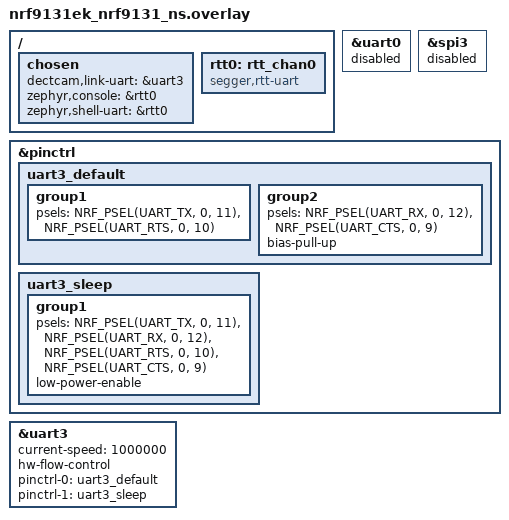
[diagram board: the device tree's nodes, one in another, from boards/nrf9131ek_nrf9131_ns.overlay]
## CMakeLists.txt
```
cmake_minimum_required(VERSION 3.20.0)

find_package(Zephyr REQUIRED HINTS $ENV{ZEPHYR_BASE})

project(dect_cam_rx)

target_sources(app PRIVATE
    src/main.c
    src/radio.c
    src/uart_out.c
    src/ctrl.c
)

target_include_directories(app PRIVATE ${CMAKE_CURRENT_SOURCE_DIR}/../common)
```

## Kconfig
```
# rsource, not source: plain `source` resolves against $srctree (ZEPHYR_BASE),
# whereas rsource is relative to this file.
rsource "../common/Kconfig.dectcam"

menu "DECT camera receiver"

config DECTCAM_RX_UART_BAUD
	int "Baud rate of the VCOM1 link to the PC"
	default 1000000
	help
	  1 Mbaud is the nRF9151 UARTE maximum and was measured to carry
	  81 kB/s losslessly through the DK's interface MCU, provided
	  hardware flow control is enabled.

config DECTCAM_RX_RING_SIZE
	int "Output ring buffer size (bytes)"
	default 16384
	help
	  Absorbs bursts from the radio while the 1 Mbaud VCOM drains.

	  When it overflows the NEWEST packet is dropped rather than
	  corrupting what is already queued, because a partial packet at the
	  PC costs a resynchronisation.

config DECTCAM_RX_STATS_PACKETS
	bool "Send link statistics to the PC"
	default y
	help
	  Emit a STATS packet about once a second carrying RSSI, SNR and PDC
	  counters, so the viewer HUD can show link quality.

endmenu

menu "Zephyr Kernel"
source "Kconfig.zephyr"
endmenu
```

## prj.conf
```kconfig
# DECT camera receiver

CONFIG_TFM_PROFILE_TYPE_MINIMAL=y

# Modem + DECT NR+ PHY
CONFIG_NRF_MODEM_LIB=y
CONFIG_NRF_MODEM_LINK_BINARY_DECT_PHY=y
CONFIG_MODEM_ANTENNA=n

CONFIG_HWINFO=y

# Link uart -> VCOM1 -> USB. Async so EasyDMA streams without a per-byte
# interrupt. Which UART instance that is depends on the board, so the
# per-instance switches live in boards/<board>.conf next to the overlay that
# chooses it.
CONFIG_SERIAL=y
CONFIG_UART_ASYNC_API=y
CONFIG_RING_BUFFER=y

CONFIG_LOG=y
CONFIG_LOG_BUFFER_SIZE=4096
# Without this Zephyr renders every %f in a log message as the literal
# "*float*", which silently destroys all the rate statistics.
CONFIG_CBPRINTF_FP_SUPPORT=y
# Deferred: logging happens on VCOM0 and must never stall the radio callback
# or the VCOM1 data path.
CONFIG_LOG_MODE_DEFERRED=y

CONFIG_MAIN_STACK_SIZE=4096
CONFIG_SYSTEM_WORKQUEUE_STACK_SIZE=2048

CONFIG_ASSERT=y
CONFIG_RESET_ON_FATAL_ERROR=n
```

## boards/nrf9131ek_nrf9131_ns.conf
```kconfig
# Per-instance UART switches for the nRF9131 EK, where the link is uart3.
#
# Instance 2 is not available here: on the nRF91 each instance number is shared
# by SPIM, SPIS, TWIM, TWIS and UARTE, and the EK spends instance 2 on i2c2 for
# the nPM1300 PMIC. Instance 3 is spent on spi3 for an external flash that the
# board already leaves disabled, so the overlay reclaims it.
#
# Stated explicitly even though nothing here enables interrupt-driven UART
# today: on the transmitter, adding the shell flipped the link uart to
# interrupt-driven and silently broke the async API. Pin it down so the same
# trap cannot be sprung by a future addition.
CONFIG_UART_3_INTERRUPT_DRIVEN=n
CONFIG_UART_3_ASYNC=y

# See the note in the overlay: the EK corrupts large packets with the
# low-power async mode on.
CONFIG_UART_3_NRF_ASYNC_LOW_POWER=n

# Console over RTT: uart0 now carries video, and the console was unusable
# during streaming anyway.
CONFIG_USE_SEGGER_RTT=y
CONFIG_RTT_CONSOLE=y
CONFIG_UART_CONSOLE=n
```

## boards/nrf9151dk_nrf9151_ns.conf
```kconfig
# Per-instance UART switches for the nRF9151 DK, where the link is uart2.
#
# These cannot live in prj.conf: the symbol name carries the instance number,
# and the nRF9131 EK has to use uart3 because instance 2 is its PMIC i2c.
#
# Stated explicitly even though nothing here enables interrupt-driven UART
# today: on the transmitter, adding the shell flipped the link uart to
# interrupt-driven and silently broke the async API. Pin it down so the same
# trap cannot be sprung by a future addition.
CONFIG_UART_2_INTERRUPT_DRIVEN=n
CONFIG_UART_2_ASYNC=y
```

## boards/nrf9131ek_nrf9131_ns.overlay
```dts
/*
 * Receiver on the nRF9131 EK (PCA10165): video over VCOM0, console over RTT.
 *
 *   P0.11 = TX  -> VCOM0 -> host
 *   P0.12 = RX  <- VCOM0 <- host
 *   P0.10 = RTS
 *   P0.09 = CTS
 *
 * No wiring: the receiver needs no header pins at all, on either connector.
 *
 * Why not VCOM1, which is where the DK puts it
 * ---------------------------------------------
 * VCOM1 works, but only for a trickle. Measured with video flowing, the
 * receiver checked its own CRC on every packet the instant the modem handed it
 * over and found not one bad -- 951 fragments queued, 0 corrupt, DECT CRC
 * errors 0, outbound ring never above empty -- and the PC still saw 553 of
 * those 951 arrive with a broken CRC. Clean in, clean out, ruined in between.
 *
 * The reason is that the EK does not connect RTS/CTS on VCOM1. Nothing can
 * tell the receiver to wait, so whenever the interface MCU is busy the bytes
 * in flight are simply gone. It is not a bandwidth problem and it does not
 * respond to the usual levers: baud 1 M, 460800 and 115200 all fail, and the
 * slower ones fail harder; fragment payloads of 687 and 128 bytes fail alike;
 * chunk sizes of 512 and 2048 make no difference; nor does turning off the
 * low-power async mode. Only the tiny packets sent while the line is otherwise
 * idle -- metadata, statistics -- survive reliably.
 *
 * uart0 is the console on VCOM0, and unlike uart1 the board's own device tree
 * gives it a full four-wire pinctrl including RTS and CTS. If those are wired
 * through, this is the port that can carry video. The console moves to RTT,
 * which costs nothing here: it was unusable during streaming anyway, because
 * both virtual COM ports share one USB device and the video starves the
 * console.
 *
 * Instance 3 rather than 2, as everywhere on this board: on the nRF91 each
 * instance number is shared by SPIM, SPIS, TWIM, TWIS and UARTE, instance 2 is
 * the nPM1300's i2c2, and instance 3 is only an already-disabled flash.
 */

/ {
	chosen {
		/* Which instance carries the video, so the source does not have
		 * to know. The two boards cannot agree on a number. */
		dectcam,link-uart = &uart3;

		zephyr,console = &rtt0;
		zephyr,shell-uart = &rtt0;
	};

	rtt0: rtt_chan0 {
		compatible = "segger,rtt-uart";
		status = "okay";
	};
};

/* uart0 owns the VCOM0 pads by default; uart3 is taking them over. */
&uart0 {
	status = "disabled";
};

/* Frees instance 3 for uart3. Only the external flash used it, and that flash
 * is already disabled in the board's device tree. */
&spi3 {
	status = "disabled";
};

&pinctrl {
	uart3_default: uart3_default {
		group1 {
			psels = <NRF_PSEL(UART_TX, 0, 11)>,
				<NRF_PSEL(UART_RTS, 0, 10)>;
		};
		group2 {
			psels = <NRF_PSEL(UART_RX, 0, 12)>,
				<NRF_PSEL(UART_CTS, 0, 9)>;
			bias-pull-up;
		};
	};

	uart3_sleep: uart3_sleep {
		group1 {
			psels = <NRF_PSEL(UART_TX, 0, 11)>,
				<NRF_PSEL(UART_RX, 0, 12)>,
				<NRF_PSEL(UART_RTS, 0, 10)>,
				<NRF_PSEL(UART_CTS, 0, 9)>;
			low-power-enable;
		};
	};
};

&uart3 {
	status = "okay";
	current-speed = <1000000>;
	hw-flow-control;
	pinctrl-0 = <&uart3_default>;
	pinctrl-1 = <&uart3_sleep>;
	pinctrl-names = "default", "sleep";
};
```

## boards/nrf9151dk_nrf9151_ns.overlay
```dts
/*
 * Receiver: uart2 routed to the nRF9151 DK's VCOM1 pins, so the video stream
 * leaves the board over the same USB-C cable that powers it.
 *
 *   P0.29 = TX  -> VCOM1 -> host
 *   P0.28 = RX  <- VCOM1 <- host
 *   P0.16 = RTS
 *   P0.17 = CTS
 *
 * Verified on hardware: these pads do reach VCOM1, which appears as the
 * SECOND of the two serial ports the DK enumerates.
 *
 * uart1 would be the natural choice for these pins, but
 * nrf9151dk_nrf9151_ns.dts disables it because TF-M claims it for secure
 * logging. uart2 is free and the nRF91 pin matrix allows any pad.
 *
 * hw-flow-control is REQUIRED, not optional. Measured over 20 s of continuous
 * 1 Mbaud traffic:
 *     without RTS/CTS : 80.4 kB/s, 13.1 % of blocks lost
 *     with    RTS/CTS : 81.0 kB/s, 0.00 % lost
 * Without it the USB path silently discards bytes and video is unusable.
 */

/ {
	chosen {
		/* Which instance carries the video, so the source does not have to
		 * know. The nRF9131 EK cannot use uart2 -- instance 2 is its PMIC
		 * i2c -- so the number is a board property, not an application one. */
		dectcam,link-uart = &uart2;
	};
};

&pinctrl {
	uart2_default: uart2_default {
		group1 {
			psels = <NRF_PSEL(UART_TX, 0, 29)>,
				<NRF_PSEL(UART_RTS, 0, 16)>;
		};
		group2 {
			psels = <NRF_PSEL(UART_RX, 0, 28)>,
				<NRF_PSEL(UART_CTS, 0, 17)>;
			bias-pull-up;
		};
	};

	uart2_sleep: uart2_sleep {
		group1 {
			psels = <NRF_PSEL(UART_TX, 0, 29)>,
				<NRF_PSEL(UART_RX, 0, 28)>,
				<NRF_PSEL(UART_RTS, 0, 16)>,
				<NRF_PSEL(UART_CTS, 0, 17)>;
			low-power-enable;
		};
	};
};

&uart2 {
	status = "okay";
	current-speed = <1000000>;
	hw-flow-control;
	pinctrl-0 = <&uart2_default>;
	pinctrl-1 = <&uart2_sleep>;
	pinctrl-names = "default", "sleep";
};
```

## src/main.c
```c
/*
 * main.c - DECT NR+ camera link, receiver.
 *
 * SPDX-License-Identifier: Apache-2.0
 *
 * Receives dectcam packets over DECT NR+ and forwards each one verbatim to the
 * PC over VCOM1. Like the transmitter, this side does not interpret the video
 * at all: it is a pump with a statistics side-channel.
 *
 * The PC sees the SECOND serial port the DK enumerates (VCOM1), and must open
 * it with RTS/CTS enabled -- see docs/wiring.md.
 */

#include <zephyr/kernel.h>
#include <zephyr/logging/log.h>
#include <zephyr/drivers/gpio.h>

#include "radio.h"
#include "uart_out.h"
#include "ctrl.h"
#include "dectcam_cfg.h"

LOG_MODULE_REGISTER(dectcam_rx, CONFIG_DECTCAM_LOG_LEVEL);

/* LED0 = radio up, LED1 = RX activity. */
static const struct gpio_dt_spec led_up = GPIO_DT_SPEC_GET(DT_ALIAS(led0), gpios);
static const struct gpio_dt_spec led_rx = GPIO_DT_SPEC_GET(DT_ALIAS(led1), gpios);

static uint32_t s_forwarded;
static uint32_t s_malformed;

/* Packets whose CRC was already wrong when the modem handed them to us. */
static uint32_t s_rx_crc_bad;
static uint32_t s_padding_saved;

/*
 * Modem callback context: do the minimum.
 *
 * The PDC is always a whole transport block (700 B at MCS 4 / 8 subslots),
 * so a packet shorter than that arrives padded with whatever the modem put
 * after it. Forwarding the padding would waste the VCOM1 link -- which at
 * 81 kB/s is the tightest bottleneck in the system -- and would force the PC
 * decoder to resynchronise after every short fragment.
 *
 * So read the length out of the header and forward exactly the real packet.
 * The header is validated first: a corrupted length must never be trusted.
 */
static void on_pdc(const uint8_t *data, size_t len)
{
	if (len < DECTCAM_HDR_LEN || data[0] != DECTCAM_MAGIC0 || data[1] != DECTCAM_MAGIC1 ||
	    (data[DECTCAM_OFF_VERTYPE] >> 4) != DECTCAM_VERSION) {
		s_malformed++;
		return;
	}

	const uint16_t plen = dectcam_get_u16(&data[DECTCAM_OFF_PAYLOAD_LEN]);
	const size_t total = (size_t)plen + DECTCAM_OVERHEAD;

	if (plen > DECTCAM_MAX_PAYLOAD || total > len) {
		s_malformed++;
		return;
	}

	/*
	 * Acknowledgements ride the video stream, because that direction
	 * already works. Let the control logic see them on the way past; they
	 * are forwarded to the host as well, so the viewer can report what
	 * happened.
	 */
	if (data[DECTCAM_OFF_VERTYPE] % 16 == DECTCAM_TYPE_CTRL) {
		ctrl_on_air_packet(data, total);
	}

	/*
	 * Check our own CRC here, the instant the modem hands the packet over,
	 * and before it goes anywhere near the ring or the UART.
	 *
	 * This settles an argument the other measurements could not. The DECT
	 * layer reports pdc_crc_err = 0, so the radio delivered every packet
	 * intact, and yet the PC sees about 60 % of them fail this same CRC.
	 * The damage is therefore somewhere between the modem checking the
	 * packet and the PC receiving it -- and that span contains both the
	 * copy out of the modem's buffer and the whole UART path. Counting
	 * failures here splits it in two: a non-zero count means the bytes
	 * were already wrong when we got them, a zero count means we sent
	 * good data and something downstream ruined it.
	 */
	{
		const uint16_t want = dectcam_crc16(&data[DECTCAM_OFF_VERTYPE],
						    (size_t)(DECTCAM_HDR_LEN - 2u) + plen);
		const uint16_t got = dectcam_get_u16(&data[DECTCAM_OFF_PAYLOAD + plen]);

		if (want != got) {
			s_rx_crc_bad++;
		}
	}

	if (uart_out_send(data, total) == 0) {
		s_forwarded++;
		s_padding_saved += (uint32_t)(len - total);
		if ((s_forwarded & 0x0f) == 0) {
			gpio_pin_toggle_dt(&led_rx);
		}
	}
}

static void leds_init(void)
{
	if (gpio_is_ready_dt(&led_up)) {
		gpio_pin_configure_dt(&led_up, GPIO_OUTPUT_INACTIVE);
	}
	if (gpio_is_ready_dt(&led_rx)) {
		gpio_pin_configure_dt(&led_rx, GPIO_OUTPUT_INACTIVE);
	}
}

#if CONFIG_DECTCAM_RX_STATS_PACKETS
static void send_stats_packet(void)
{
	struct radio_stats rs;
	struct uart_out_stats us;

	radio_get_stats(&rs);
	uart_out_get_stats(&us);

	struct dectcam_stats s = {
		.rssi_2 = rs.last_rssi_2,
		.snr = rs.last_snr,
		.pdc_ok = rs.pdc_ok,
		.pdc_crc_err = rs.pdc_crc_err,
		.frags_out = us.queued,
		.ring_peak = (uint16_t)MIN(uart_out_take_peak(), UINT16_MAX),
		.rx_crc_bad = (uint16_t)MIN(s_rx_crc_bad, UINT16_MAX),
	};
	uint8_t body[DECTCAM_STATS_LEN];
	uint8_t pkt[DECTCAM_STATS_LEN + DECTCAM_OVERHEAD];

	dectcam_stats_pack(body, &s);

	const size_t n = dectcam_encode(pkt, sizeof(pkt), DECTCAM_TYPE_STATS, 0, 0, 0, body,
					sizeof(body));

	if (n) {
		uart_out_send(pkt, n);
	}
}
#endif

int main(void)
{
	LOG_INF("DECT camera receiver starting");

	leds_init();

	ctrl_init();

	if (uart_out_init() != 0) {
		LOG_ERR("uart init failed; halting");
		return -EIO;
	}
	uart_out_set_rx_cb(ctrl_feed_host);

	if (radio_init(on_pdc) != 0) {
		LOG_ERR("radio init failed; halting");
		return -EIO;
	}

	if (radio_start_rx() != 0) {
		LOG_ERR("could not start RX; halting");
		return -EIO;
	}
	gpio_pin_set_dt(&led_up, 1);

	LOG_INF("receiving; forwarding to VCOM1");

	int64_t last_stats = k_uptime_get();
	int64_t last_statpkt = k_uptime_get();
	uint32_t last_pdc_ok;
	uint64_t last_bytes;

	{
		struct radio_stats rs;

		radio_get_stats(&rs);
		last_pdc_ok = rs.pdc_ok;
		last_bytes = rs.rx_bytes;
	}

	for (;;) {
		/*
		 * 20 ms rather than 100: control telegrams are repeated from
		 * here, and the transmitter's listen window is only 20 ms wide
		 * every 250 ms, so a slower loop would miss most of them.
		 */
		k_msleep(20);

		ctrl_poll();

		const int64_t now = k_uptime_get();

#if CONFIG_DECTCAM_RX_STATS_PACKETS
		if (now - last_statpkt >= 1000) {
			send_stats_packet();
			last_statpkt = now;
		}
#endif

#if CONFIG_DECTCAM_STATS_INTERVAL_MS > 0
		if (now - last_stats >= CONFIG_DECTCAM_STATS_INTERVAL_MS) {
			const double secs = (now - last_stats) / 1000.0;
			struct radio_stats rs;
			struct uart_out_stats us;

			radio_get_stats(&rs);
			uart_out_get_stats(&us);

			LOG_INF("rx %.1f pkt/s, %.1f kB/s | rssi %d.%d dBm snr %d.%02d dB | "
				"pdc ok %u crc %u | pcc ok %u crc %u | "
				"uart q %u drop %u | malformed %u | pad saved %u kB | "
				"rx restarts %u",
				(rs.pdc_ok - last_pdc_ok) / secs,
				(rs.rx_bytes - last_bytes) / secs / 1000.0, rs.last_rssi_2 / 2,
				(rs.last_rssi_2 & 1) * 5, rs.last_snr / 4,
				(rs.last_snr % 4) * 25, rs.pdc_ok, rs.pdc_crc_err, rs.pcc_ok,
				rs.pcc_crc_err, us.queued, us.dropped, s_malformed,
				s_padding_saved / 1024, rs.rx_restarts);

			last_pdc_ok = rs.pdc_ok;
			last_bytes = rs.rx_bytes;
			last_stats = now;
		}
#endif
	}

	return 0;
}
```

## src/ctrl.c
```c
/*
 * ctrl.c - control from the PC, receiver side.
 *
 * SPDX-License-Identifier: Apache-2.0
 *
 * The operator's commands arrive here, on the same USB serial port that
 * carries video the other way, and are relayed over the air to the
 * transmitter. This side is the one that knows whether a command worked,
 * because it can see the acknowledgement come back in the video stream.
 *
 * A telegram is repeated until it is acknowledged or the attempt times out.
 * That is not belt and braces: the transmitter only listens for 20 ms out of
 * every 250, so a single copy would usually be missed.
 */

#include <zephyr/kernel.h>
#include <zephyr/logging/log.h>

#include "ctrl.h"
#include "radio.h"
#include "dectcam_cfg.h"

LOG_MODULE_DECLARE(dectcam_rx, CONFIG_DECTCAM_LOG_LEVEL);

/*
 * A burst of copies, close enough together that any listen window at the far
 * end catches several.
 *
 * The transmitter listens for 30 ms out of every 200. Copies 25 ms apart mean
 * at least one lands in every window, and 40 of them span a full second --
 * five windows. Reception is stopped for that second, so this is deliberately
 * a one-off cost rather than a background trickle.
 */
#define BURST_COUNT  40
#define BURST_GAP_MS 25

/* How long to wait for the acknowledgement, and how many bursts to try. */
#define ACK_WAIT_MS  1500
#define MAX_BURSTS   3

/*
 * Carrier rollback deadline.
 *
 * Deliberately shorter than the transmitter's 6 s trial. If the move fails,
 * this end returns first and is already listening on the old carrier by the
 * time the far end follows -- the two converge instead of crossing over, which
 * is what would happen if both used the same deadline and drifted apart.
 */
#define CARRIER_TRIAL_MS 4000

static struct ctrl_stats s_stats;

/* The telegram currently being sent, if any. */
static bool s_busy;
static uint8_t s_opcode;
static uint32_t s_arg;
static uint8_t s_seq;
static int s_bursts_done;
static int64_t s_wait_until;

/* Carrier trial state. */
static bool s_carrier_trial;
static uint16_t s_carrier_previous;
static uint16_t s_carrier_target;
static int64_t s_carrier_deadline;
static uint32_t s_pdc_at_switch;

/*
 * Sequence numbers for telegrams this end originates rather than relays --
 * currently only the carrier confirmation. Kept well away from the host's
 * numbering by counting down from the top, so the two cannot collide and
 * suppress one another as duplicates.
 */
static uint8_t s_own_seq = 255;

/* Reassembles packets arriving from the host, which need not be aligned. */
static uint8_t s_host_buf[128];
static size_t s_host_len;

/*
 * Start sending a telegram.
 *
 * `seq` comes from the host and is carried through unchanged, so the
 * acknowledgement that eventually comes back can be matched to the command
 * that caused it -- by the transmitter for de-duplication, and by the operator
 * at the far end of the USB cable.
 *
 * De-duplication at the far end compares against the previous sequence only,
 * so a host that restarts and reuses a number does not lose a command; it
 * would have to reuse the number twice in a row.
 */
static void send_burst(uint8_t opcode, uint8_t seq, uint32_t arg)
{
	uint8_t pkt[DECTCAM_CTRL_LEN + DECTCAM_OVERHEAD];
	const size_t n = dectcam_encode_ctrl(pkt, sizeof(pkt), opcode, seq, arg);

	if (n == 0) {
		return;
	}
	if (radio_send_ctrl_burst(pkt, n, BURST_COUNT, BURST_GAP_MS) == 0) {
		s_stats.sent++;
	}
}

static void start(uint8_t opcode, uint8_t seq, uint32_t arg)
{
	s_busy = true;
	s_opcode = opcode;
	s_arg = arg;
	s_seq = seq;
	s_bursts_done = 0;
	s_wait_until = 0; /* burst immediately */
}

/*
 * Begin a carrier change.
 *
 * Unlike every other command, this one does NOT wait for an acknowledgement
 * before acting -- it cannot. The far end applies the new carrier the moment
 * it hears the telegram and starts transmitting there, including its
 * acknowledgement. This end is still on the old carrier and so never hears it.
 * Waiting for one leaves the two ends on different channels with no way to
 * reach each other, which is exactly what happened the first time this was
 * tried: the link went dead and only a reset brought it back.
 *
 * So both ends move on their own clocks instead. This one announces the change
 * for the length of one burst, then retunes regardless. Each side then watches
 * for traffic and returns to the old carrier on its own if none appears -- this
 * end first, so the two converge on the old channel rather than crossing over.
 */
static void begin_carrier_change(uint8_t seq, uint16_t carrier)
{
	s_carrier_previous = radio_carrier();
	s_carrier_target = carrier;

	LOG_WRN("announcing carrier %u -> %u", s_carrier_previous, carrier);

	uint8_t pkt[DECTCAM_CTRL_LEN + DECTCAM_OVERHEAD];
	const size_t n = dectcam_encode_ctrl(pkt, sizeof(pkt), DECTCAM_CTRL_SET_CARRIER,
					     seq, carrier);

	if (n == 0) {
		return;
	}

	/* One burst on the old carrier: five of the far end's listen windows. */
	radio_send_ctrl_burst(pkt, n, BURST_COUNT, BURST_GAP_MS);
	s_stats.sent++;

	/* Now follow it, and start the clock. */
	struct radio_stats rs;

	radio_get_stats(&rs);
	s_pdc_at_switch = rs.pdc_ok;
	s_carrier_trial = true;
	s_carrier_deadline = k_uptime_get() + CARRIER_TRIAL_MS;
	s_stats.carrier_moves++;

	radio_set_carrier(carrier);
	LOG_WRN("now on %u; returning to %u in %d ms unless video appears", carrier,
		s_carrier_previous, CARRIER_TRIAL_MS);
}

void ctrl_init(void)
{
	s_host_len = 0;
}

/*
 * Command from the host, waiting to be acted on.
 *
 * ctrl_feed_host() runs in the UART interrupt. Acting on a command there is
 * not merely impolite, it is fatal: a carrier change transmits a burst, and
 * the burst sleeps between copies. k_msleep() from an interrupt takes the
 * board down, which is precisely what happened -- the receiver went silent and
 * only a reset brought it back, while the transmitter carried on happily
 * announcing itself on a carrier nobody was listening to.
 *
 * So the interrupt parks the command and the main loop runs it.
 */
static volatile bool s_inbox_full;
static struct dectcam_ctrl s_inbox;

static void handle_from_host(const struct dectcam_ctrl *c)
{
	s_stats.from_host++;

	if (s_busy || s_inbox_full) {
		LOG_WRN("a command is already in flight; ignoring opcode %u", c->opcode);
		return;
	}

	s_inbox = *c;
	s_inbox_full = true;
}

static void process_inbox(void)
{
	if (!s_inbox_full) {
		return;
	}

	const struct dectcam_ctrl c = s_inbox;

	s_inbox_full = false;

	if (c.opcode == DECTCAM_CTRL_SET_CARRIER) {
		begin_carrier_change(c.seq, (uint16_t)c.arg32);
	} else {
		start(c.opcode, c.seq, c.arg32);
	}
}

void ctrl_feed_host(const uint8_t *data, size_t len)
{
	for (size_t i = 0; i < len; i++) {
		if (s_host_len < sizeof(s_host_buf)) {
			s_host_buf[s_host_len++] = data[i];
		} else {
			/* Nothing valid in a full buffer: start over. */
			s_host_len = 0;
		}

		/* Try to pull a packet out of what we have so far. */
		while (s_host_len >= DECTCAM_HDR_LEN) {
			struct dectcam_pkt pkt;
			size_t consumed = 0;
			const int rc = dectcam_decode(s_host_buf, s_host_len, &pkt, &consumed);

			if (rc == DECTCAM_ERR_SHORT) {
				break;
			}
			if (rc != DECTCAM_OK) {
				/* Resynchronise one byte at a time. */
				memmove(s_host_buf, s_host_buf + 1, --s_host_len);
				continue;
			}

			if (pkt.type == DECTCAM_TYPE_CTRL &&
			    pkt.payload_len >= DECTCAM_CTRL_LEN) {
				struct dectcam_ctrl c;

				dectcam_ctrl_unpack(pkt.payload, &c);
				handle_from_host(&c);
			}

			memmove(s_host_buf, s_host_buf + consumed, s_host_len - consumed);
			s_host_len -= consumed;
		}
	}
}

void ctrl_on_air_packet(const uint8_t *data, size_t len)
{
	struct dectcam_pkt pkt;
	size_t consumed;

	if (dectcam_decode(data, len, &pkt, &consumed) != DECTCAM_OK) {
		return;
	}
	if (pkt.type != DECTCAM_TYPE_CTRL || pkt.payload_len < DECTCAM_CTRL_LEN) {
		return;
	}

	struct dectcam_ctrl c;

	dectcam_ctrl_unpack(pkt.payload, &c);

	if (c.opcode != DECTCAM_CTRL_ACK || !s_busy || c.seq != s_seq) {
		return;
	}

	s_busy = false;
	s_stats.acked++;

	if (c.arg32 != DECTCAM_ACK_OK) {
		LOG_WRN("far end rejected opcode %u (status %u)", s_opcode,
			(unsigned)c.arg32);
	}
}

void ctrl_poll(void)
{
	const int64_t now = k_uptime_get();

	process_inbox();

	if (s_carrier_trial) {
		struct radio_stats rs;

		radio_get_stats(&rs);

		if (rs.pdc_ok > s_pdc_at_switch) {
			/* Video is arriving: the move worked. Tell the far end
			 * so it stops its own rollback timer. */
			s_carrier_trial = false;
			LOG_INF("video on carrier %u; confirming", s_carrier_target);
			send_burst(DECTCAM_CTRL_CARRIER_OK, s_own_seq--, s_carrier_target);
			if (s_own_seq < 128) {
				s_own_seq = 255;
			}
		} else if (now >= s_carrier_deadline) {
			s_carrier_trial = false;
			s_stats.carrier_rollbacks++;
			LOG_ERR("no video on %u; returning to %u", s_carrier_target,
				s_carrier_previous);
			radio_set_carrier(s_carrier_previous);
		}
	}

	if (!s_busy) {
		return;
	}

	/* Still waiting for the acknowledgement from the last burst. */
	if (now < s_wait_until) {
		return;
	}

	if (s_bursts_done >= MAX_BURSTS) {
		s_busy = false;
		s_stats.timed_out++;
		LOG_WRN("no acknowledgement for opcode %u after %d bursts", s_opcode,
			MAX_BURSTS);
		return;
	}

	s_bursts_done++;
	send_burst(s_opcode, s_seq, s_arg);
	s_wait_until = k_uptime_get() + ACK_WAIT_MS;
}

void ctrl_get_stats(struct ctrl_stats *out)
{
	if (out) {
		*out = s_stats;
	}
}
```

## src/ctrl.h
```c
/*
 * ctrl.h - control from the PC, receiver side.
 *
 * SPDX-License-Identifier: Apache-2.0
 */

#ifndef DECTCAM_RX_CTRL_H
#define DECTCAM_RX_CTRL_H

#include <stdint.h>
#include <stddef.h>

void ctrl_init(void);

/*
 * Feed bytes arriving from the PC on the data port.
 *
 * That port is normally write-only from this end -- it carries video to the
 * host -- but it is a full-duplex UART, so the host can send control packets
 * back along it without any extra wiring.
 */
void ctrl_feed_host(const uint8_t *data, size_t len);

/* Hand a packet that arrived over the air to the control logic. */
void ctrl_on_air_packet(const uint8_t *data, size_t len);

/* Give the control logic a slice of the main loop: repeats and timeouts. */
void ctrl_poll(void);

struct ctrl_stats {
	uint32_t from_host;
	uint32_t sent;          /* telegrams put on the air, including repeats */
	uint32_t acked;
	uint32_t timed_out;
	uint32_t carrier_moves;
	uint32_t carrier_rollbacks;
};

void ctrl_get_stats(struct ctrl_stats *out);

#endif /* DECTCAM_RX_CTRL_H */
```

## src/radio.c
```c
/*
 * radio.c - DECT NR+ PHY receive wrapper.
 *
 * SPDX-License-Identifier: Apache-2.0
 *
 * Keeps the PHY in continuous receive and hands every good PDC to a callback.
 */

#include <zephyr/kernel.h>
#include <zephyr/logging/log.h>
#include <zephyr/drivers/hwinfo.h>

#include <nrf_modem_dect_phy.h>
#include <modem/nrf_modem_lib.h>

#include "radio.h"
#include "dectcam_cfg.h"

LOG_MODULE_REGISTER(radio, CONFIG_DECTCAM_LOG_LEVEL);

BUILD_ASSERT(CONFIG_DECTCAM_CARRIER != 0,
	     "CONFIG_DECTCAM_CARRIER must be set according to local regulations");

static uint16_t s_device_id;
static struct radio_stats s_stats;
static radio_pdc_cb_t s_pdc_cb;

/* Live carrier. Seeded from Kconfig, retuned at run time when the operator
 * moves the link -- see ctrl.c for the sequence that keeps both ends together.
 */
static uint16_t s_carrier = CONFIG_DECTCAM_CARRIER;

static K_SEM_DEFINE(op_sem, 0, 1);
static volatile int s_op_err;
static bool s_fatal;

/*
 * Whether reception should be running.
 *
 * Continuous RX ends on its own after `duration` and is restarted from a work
 * item. That auto-restart has to be suppressed while the radio is borrowed for
 * a transmit, or the restart races the transmit and one of the two is
 * rejected.
 */
static volatile bool s_rx_wanted;

#define RX_HANDLE 1u
#define TX_HANDLE 0u

/*
 * Continuous RX still ends after `duration`, so it is restarted from a work
 * item when it completes. Using the modem's maximum keeps the restart rate --
 * and therefore the gap in coverage -- as low as possible.
 */
#define RX_DURATION_S 60

static void rx_restart_work_fn(struct k_work *work);
static K_WORK_DEFINE(rx_restart_work, rx_restart_work_fn);

static void handle_common(int err)
{
	s_op_err = err;
	k_sem_give(&op_sem);
}

static void dect_phy_event_handler(const struct nrf_modem_dect_phy_event *evt)
{
	switch (evt->id) {
	case NRF_MODEM_DECT_PHY_EVT_INIT:
		if (evt->init.err) {
			LOG_ERR("PHY init failed: %d", evt->init.err);
			s_fatal = true;
		}
		handle_common(evt->init.err);
		break;
	case NRF_MODEM_DECT_PHY_EVT_CONFIGURE:
		if (evt->configure.err) {
			LOG_ERR("PHY configure failed: %d", evt->configure.err);
			s_fatal = true;
		}
		handle_common(evt->configure.err);
		break;
	case NRF_MODEM_DECT_PHY_EVT_ACTIVATE:
		if (evt->activate.err) {
			LOG_ERR("PHY activate failed: %d", evt->activate.err);
			s_fatal = true;
		}
		handle_common(evt->activate.err);
		break;

	case NRF_MODEM_DECT_PHY_EVT_PCC:
		s_stats.pcc_ok++;
		s_stats.last_rssi_2 = evt->pcc.rssi_2;
		s_stats.last_snr = evt->pcc.snr;
		break;
	case NRF_MODEM_DECT_PHY_EVT_PCC_ERROR:
		s_stats.pcc_crc_err++;
		break;

	case NRF_MODEM_DECT_PHY_EVT_PDC:
		s_stats.pdc_ok++;
		s_stats.rx_bytes += evt->pdc.len;
		s_stats.last_rssi_2 = evt->pdc.rssi_2;
		s_stats.last_snr = evt->pdc.snr;
		if (s_pdc_cb) {
			s_pdc_cb((const uint8_t *)evt->pdc.data, evt->pdc.len);
		}
		break;
	case NRF_MODEM_DECT_PHY_EVT_PDC_ERROR:
		s_stats.pdc_crc_err++;
		break;

	case NRF_MODEM_DECT_PHY_EVT_COMPLETED:
		/*
		 * Either the RX window elapsed or a transmit finished. Release
		 * anyone waiting, then restart reception -- but only if it is
		 * still wanted, so a deliberate stop is not undone.
		 *
		 * Restarting happens from a work item because calling back into
		 * the modem from its own callback is not allowed.
		 */
		handle_common(evt->op_complete.err);
		if (s_rx_wanted) {
			k_work_submit(&rx_restart_work);
		}
		break;
	case NRF_MODEM_DECT_PHY_EVT_CANCELED:
		handle_common(evt->cancel.err);
		break;
	case NRF_MODEM_DECT_PHY_EVT_REJECT:
		LOG_WRN("operation rejected");
		break;
	default:
		break;
	}
}

static int step(const char *what, int err)
{
	if (err) {
		LOG_ERR("%s returned %d", what, err);
		return err;
	}
	if (k_sem_take(&op_sem, K_SECONDS(5)) != 0) {
		LOG_ERR("%s timed out waiting for its event", what);
		return -ETIMEDOUT;
	}
	if (s_fatal) {
		return -EIO;
	}
	return s_op_err;
}

int radio_start_rx(void)
{
	struct nrf_modem_dect_phy_rx_params rx = {
		.start_time = 0,
		.handle = RX_HANDLE,
		.network_id = CONFIG_DECTCAM_NETWORK_ID,
		.mode = NRF_MODEM_DECT_PHY_RX_MODE_CONTINUOUS,
		.rssi_interval = NRF_MODEM_DECT_PHY_RSSI_INTERVAL_OFF,
		.link_id = NRF_MODEM_DECT_PHY_LINK_UNSPECIFIED,
		.rssi_level = -60,
		.carrier = s_carrier,
		.duration = (uint32_t)RX_DURATION_S * MSEC_PER_SEC *
			    NRF_MODEM_DECT_MODEM_TIME_TICK_RATE_KHZ,
		.filter.short_network_id = CONFIG_DECTCAM_NETWORK_ID & 0xff,
		.filter.is_short_network_id_used = 1,
		/* Broadcast: accept from any transmitter on this network. */
		.filter.receiver_identity = 0,
	};

	s_rx_wanted = true;
	k_sem_reset(&op_sem);

	int err = nrf_modem_dect_phy_rx(&rx);

	if (err) {
		LOG_ERR("nrf_modem_dect_phy_rx failed: %d", err);
	}
	return err;
}

int radio_stop_rx(void)
{
	if (!s_rx_wanted) {
		return 0;
	}
	s_rx_wanted = false;

	int err = nrf_modem_dect_phy_cancel(RX_HANDLE);

	if (err) {
		LOG_WRN("cancel returned %d", err);
		return err;
	}

	/*
	 * Wait for the operation to actually stop. Transmitting while the
	 * receiver still owns the radio gets the transmit rejected.
	 */
	if (k_sem_take(&op_sem, K_MSEC(500)) != 0) {
		LOG_WRN("receive did not stop in time");
		return -ETIMEDOUT;
	}
	return 0;
}

/* One transmission. The caller owns stopping and restarting reception. */
static int tx_once(const uint8_t *data, size_t len)
{
	struct dectcam_phy_hdr_type1 hdr = {
		.header_format = 0,
		.packet_length_type = 0,
		.packet_length = DECTCAM_PKT_LEN_FIELD,
		.short_network_id = (CONFIG_DECTCAM_NETWORK_ID & 0xff),
		.transmitter_id_hi = (s_device_id >> 8),
		.transmitter_id_lo = (s_device_id & 0xff),
		.transmit_power = CONFIG_DECTCAM_TX_POWER,
		.reserved = 0,
		.df_mcs = CONFIG_DECTCAM_MCS,
	};

	struct nrf_modem_dect_phy_tx_params tx = {
		.start_time = 0,
		.handle = TX_HANDLE,
		.network_id = CONFIG_DECTCAM_NETWORK_ID,
		.phy_type = 0,
		.carrier = s_carrier,
		.phy_header = (union nrf_modem_dect_phy_hdr *)&hdr,
		.data = (void *)data,
		.data_size = len,
		.lbt_rssi_threshold_max = 0,
		.lbt_period = 0,
	};

	k_sem_reset(&op_sem);

	int err = nrf_modem_dect_phy_tx(&tx);

	if (err == 0) {
		if (k_sem_take(&op_sem, K_MSEC(500)) != 0) {
			err = -ETIMEDOUT;
		} else {
			err = s_op_err;
		}
	}

	if (err) {
		s_stats.ctrl_tx_err++;
	} else {
		s_stats.ctrl_tx++;
	}
	return err;
}

int radio_send_ctrl_burst(const uint8_t *data, size_t len, int count, uint32_t gap_ms)
{
	if (len == 0 || len > (size_t)DECTCAM_TBS_BYTES || count <= 0) {
		return -EINVAL;
	}

	const bool was_receiving = s_rx_wanted;

	if (was_receiving && radio_stop_rx() != 0) {
		LOG_WRN("could not stop reception; not transmitting");
		return -EBUSY;
	}

	int sent = 0;

	for (int i = 0; i < count; i++) {
		if (tx_once(data, len) == 0) {
			sent++;
		}
		if (i + 1 < count && gap_ms) {
			k_msleep(gap_ms);
		}
	}

	if (was_receiving) {
		radio_start_rx();
	}

	if (sent == 0) {
		LOG_WRN("control burst: nothing got out");
		return -EIO;
	}
	return 0;
}

int radio_set_carrier(uint16_t carrier)
{
	if (carrier == 0) {
		return -EINVAL;
	}
	if (carrier == s_carrier) {
		return 0;
	}

	const bool was_receiving = s_rx_wanted;

	if (was_receiving) {
		radio_stop_rx();
	}
	s_carrier = carrier;
	LOG_INF("carrier -> %u", carrier);

	if (was_receiving) {
		return radio_start_rx();
	}
	return 0;
}

uint16_t radio_carrier(void)
{
	return s_carrier;
}

static void rx_restart_work_fn(struct k_work *work)
{
	ARG_UNUSED(work);
	s_stats.rx_restarts++;
	radio_start_rx();
}

int radio_init(radio_pdc_cb_t cb)
{
	int err;

	s_pdc_cb = cb;

	err = nrf_modem_lib_init();
	if (err) {
		LOG_ERR("nrf_modem_lib_init failed: %d", err);
		return err;
	}

	err = nrf_modem_dect_phy_event_handler_set(dect_phy_event_handler);
	if (err) {
		LOG_ERR("event_handler_set failed: %d", err);
		return err;
	}

	err = step("dect_phy_init", nrf_modem_dect_phy_init());
	if (err) {
		return err;
	}

	struct nrf_modem_dect_phy_config_params cfg = {
		.band_group_index = CONFIG_DECTCAM_BAND_GROUP_INDEX,
		.harq_rx_process_count = 4,
		.harq_rx_expiry_time_us = 5000000,
	};

	err = step("dect_phy_configure", nrf_modem_dect_phy_configure(&cfg));
	if (err) {
		return err;
	}

	err = step("dect_phy_activate",
		   nrf_modem_dect_phy_activate(NRF_MODEM_DECT_PHY_RADIO_MODE_LOW_LATENCY));
	if (err) {
		return err;
	}

	hwinfo_get_device_id((void *)&s_device_id, sizeof(s_device_id));

	LOG_INF("DECT PHY up: device id %u, carrier %d, MCS %d, %d subslots (%d B TBS)",
		s_device_id, CONFIG_DECTCAM_CARRIER, CONFIG_DECTCAM_MCS,
		CONFIG_DECTCAM_PACKET_LEN_SUBSLOTS, DECTCAM_TBS_BYTES);

	return 0;
}

uint16_t radio_device_id(void)
{
	return s_device_id;
}

void radio_get_stats(struct radio_stats *out)
{
	if (out) {
		*out = s_stats;
	}
}
```

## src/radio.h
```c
/*
 * radio.h - DECT NR+ PHY receive wrapper.
 *
 * SPDX-License-Identifier: Apache-2.0
 */

#ifndef DECTCAM_RADIO_H
#define DECTCAM_RADIO_H

#include <stdint.h>
#include <stddef.h>

/*
 * Called from the modem event handler for every PDC that passes CRC.
 * Keep it short: it runs in the modem callback context.
 */
typedef void (*radio_pdc_cb_t)(const uint8_t *data, size_t len);

int radio_init(radio_pdc_cb_t cb);

/* Start (or restart) continuous reception. */
int radio_start_rx(void);

/* Stop the current receive operation and wait for it to wind down. */
int radio_stop_rx(void);

/*
 * Send the same control telegram `count` times, `gap_ms` apart.
 *
 * The far end listens only in short windows between video bursts, so a single
 * copy would usually be missed. Reception is stopped once for the whole burst
 * rather than once per copy: tearing it down and building it back up again for
 * every repeat cost more time than the transmissions themselves and left the
 * video badly disrupted.
 *
 * Video is not received for the duration of the burst. That is the price of
 * having one radio, and it is only paid when the operator changes something.
 */
int radio_send_ctrl_burst(const uint8_t *data, size_t len, int count, uint32_t gap_ms);

/* Retune the receiver. The far end must be moved separately and first. */
int radio_set_carrier(uint16_t carrier);

uint16_t radio_carrier(void);

uint16_t radio_device_id(void);

struct radio_stats {
	uint32_t pdc_ok;
	uint32_t pdc_crc_err;
	uint32_t pcc_ok;
	uint32_t pcc_crc_err;
	uint32_t rx_restarts;
	uint64_t rx_bytes;
	uint32_t ctrl_tx;     /* control telegrams put on the air */
	uint32_t ctrl_tx_err;
	int16_t last_rssi_2;  /* dBm * 2 */
	int16_t last_snr;     /* dB * 4  */
};

void radio_get_stats(struct radio_stats *out);

#endif /* DECTCAM_RADIO_H */
```

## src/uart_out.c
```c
/*
 * uart_out.c - buffered UART transmission to the PC over VCOM1.
 *
 * SPDX-License-Identifier: Apache-2.0
 *
 * The modem callback must return quickly, so it only appends to a ring buffer.
 * A dedicated thread drains that into the UART using the async API, so
 * EasyDMA does the work.
 *
 * Packets are queued atomically: if a whole packet does not fit, it is dropped
 * entirely rather than truncated. A torn packet would cost the PC decoder a
 * resynchronisation and would very likely corrupt the frame either way, so
 * dropping is strictly better.
 */

#include <zephyr/kernel.h>
#include <zephyr/device.h>
#include <zephyr/drivers/uart.h>
#include <zephyr/logging/log.h>
#include <zephyr/sys/ring_buffer.h>

#include "uart_out.h"
#include "dectcam_proto.h"

LOG_MODULE_DECLARE(dectcam_rx, CONFIG_DECTCAM_LOG_LEVEL);

/* Named by the board overlay, not here: the DK uses uart2 and the EK uart3,
 * because on the EK instance 2 belongs to the PMIC's i2c. */
static const struct device *const uart_dev = DEVICE_DT_GET(DT_CHOSEN(dectcam_link_uart));

RING_BUF_DECLARE(tx_ring, CONFIG_DECTCAM_RX_RING_SIZE);

/*
 * Guards the producer side of tx_ring. See uart_out_send() for why: the ring
 * buffer tolerates one producer, and this application has two.
 *
 * The consumer (pump_thread) needs no lock, since single-producer /
 * single-consumer is exactly the case the ring buffer is designed for once the
 * producers are serialised among themselves.
 */
static struct k_spinlock tx_lock;

/*
 * Two chunk buffers so the next DMA transfer can be prepared while the
 * current one is in flight.
 */
#define CHUNK_SZ 512
static uint8_t chunk[2][CHUNK_SZ];

static K_SEM_DEFINE(tx_done, 1, 1);
static K_SEM_DEFINE(data_ready, 0, 1);
static struct uart_out_stats s_stats;

/*
 * Reception from the host.
 *
 * This port was write-only for most of the project's life -- it exists to push
 * video at the PC -- but it is an ordinary full-duplex UART, so control from
 * the operator can come back along it without another cable. The traffic is a
 * few bytes at a time and rare, so two small DMA buffers are plenty.
 */
#define RX_BUF_SZ 64
static uint8_t rx_buf[2][RX_BUF_SZ];
static int rx_next;
static uart_out_rx_cb_t s_rx_cb;

static void uart_cb(const struct device *dev, struct uart_event *evt, void *user_data)
{
	ARG_UNUSED(user_data);

	switch (evt->type) {
	case UART_TX_DONE:
	case UART_TX_ABORTED:
		k_sem_give(&tx_done);
		break;

	case UART_RX_RDY:
		if (s_rx_cb) {
			s_rx_cb(&evt->data.rx.buf[evt->data.rx.offset], evt->data.rx.len);
		}
		break;
	case UART_RX_BUF_REQUEST:
		uart_rx_buf_rsp(dev, rx_buf[rx_next], RX_BUF_SZ);
		rx_next ^= 1;
		break;
	case UART_RX_DISABLED:
		/* Should not happen while running; restart so a transient
		 * error does not quietly remove the control path. */
		LOG_WRN("host RX disabled, restarting");
		uart_rx_enable(dev, rx_buf[0], RX_BUF_SZ, 2000);
		break;

	default:
		break;
	}
}

int uart_out_init(void)
{
	if (!device_is_ready(uart_dev)) {
		LOG_ERR("link uart not ready");
		return -ENODEV;
	}

	int err = uart_callback_set(uart_dev, uart_cb, NULL);

	if (err) {
		LOG_ERR("uart_callback_set failed: %d", err);
		return err;
	}

	/*
	 * A 2 ms idle timeout flushes a partially filled buffer, so a short
	 * command does not sit waiting for 64 bytes that will never come.
	 */
	err = uart_rx_enable(uart_dev, rx_buf[0], RX_BUF_SZ, 2000);
	if (err) {
		LOG_ERR("uart_rx_enable failed: %d", err);
		return err;
	}
	rx_next = 1;

	LOG_INF("link uart up @ %d baud (VCOM1), %d B ring, control accepted from the host",
		CONFIG_DECTCAM_RX_UART_BAUD, CONFIG_DECTCAM_RX_RING_SIZE);
	return 0;
}

void uart_out_set_rx_cb(uart_out_rx_cb_t cb)
{
	s_rx_cb = cb;
}

int uart_out_send(const uint8_t *data, size_t len)
{
	if (len == 0) {
		return 0;
	}

	/*
	 * Serialise the producers.
	 *
	 * Zephyr's ring buffer is lock-free for ONE producer and ONE consumer.
	 * There are two producers here: the modem callback forwarding video,
	 * and the main loop emitting a statistics packet once a second. When
	 * the two interleave, both compute an allocation against the same head
	 * index, the second ring_buf_put_finish() reports a size that no longer
	 * fits, and its __ASSERT_NO_MSG fires:
	 *
	 *   ASSERTION FAIL [err == 0] @ zephyr/lib/utils/ring_buffer.c:72
	 *   ZEPHYR FATAL ERROR 4: Kernel panic
	 *
	 * The window is a few instructions wide and the statistics packet is
	 * sent once a second, so this took a long time to show up: the receiver
	 * had run for hours before it landed. A spinlock is the right size of
	 * fix -- the critical section is a memcpy of at most a few hundred
	 * bytes, and the modem callback must not block.
	 */
	k_spinlock_key_t key = k_spin_lock(&tx_lock);

	/*
	 * All-or-nothing. ring_buf_put() would happily write a prefix and
	 * report a short count, which is exactly the torn packet we must
	 * avoid, so check the space first.
	 */
	if (ring_buf_space_get(&tx_ring) < len) {
		s_stats.dropped++;
		k_spin_unlock(&tx_lock, key);
		return -ENOSPC;
	}

	const uint32_t put = ring_buf_put(&tx_ring, data, len);

	if (put != len) {
		/* Should be unreachable given the check above. */
		s_stats.dropped++;
		k_spin_unlock(&tx_lock, key);
		return -ENOSPC;
	}

	s_stats.queued++;
	s_stats.bytes += len;

	/*
	 * How full the ring actually gets, not how much has been through it.
	 *
	 * Whatever is standing here is latency: bytes the radio has already
	 * delivered that the PC has not seen yet. At 40 kB/s a full 16 kB ring
	 * is four tenths of a second of delay on every frame from then on, and
	 * it does not drain on its own -- the PC reads at exactly the rate the
	 * radio delivers, so a backlog once formed is permanent.
	 */
	const uint32_t used = ring_buf_size_get(&tx_ring);

	if (used > s_stats.peak) {
		s_stats.peak = used;
	}

	k_spin_unlock(&tx_lock, key);

	k_sem_give(&data_ready);
	return 0;
}

static void pump_thread(void *a, void *b, void *c)
{
	ARG_UNUSED(a);
	ARG_UNUSED(b);
	ARG_UNUSED(c);

	int idx = 0;

	for (;;) {
		if (ring_buf_is_empty(&tx_ring)) {
			k_sem_take(&data_ready, K_MSEC(100));
			continue;
		}

		/* Wait for the previous DMA transfer to finish. */
		if (k_sem_take(&tx_done, K_MSEC(1000)) != 0) {
			LOG_WRN("UART TX stalled; is the host asserting CTS?");
			continue;
		}

		const uint32_t n = ring_buf_get(&tx_ring, chunk[idx], CHUNK_SZ);

		if (n == 0) {
			k_sem_give(&tx_done);
			continue;
		}

		if (uart_tx(uart_dev, chunk[idx], n, SYS_FOREVER_US) != 0) {
			k_sem_give(&tx_done);
			k_msleep(1);
			continue;
		}
		idx ^= 1;
	}
}

K_THREAD_DEFINE(uart_out_pump, 1024, pump_thread, NULL, NULL, NULL, 5, 0, 0);

void uart_out_get_stats(struct uart_out_stats *out)
{
	if (out) {
		*out = s_stats;
	}
}

uint32_t uart_out_take_peak(void)
{
	/*
	 * Read and clear, so the high water mark covers the interval between
	 * calls rather than all of time. A single spike while the host was
	 * still opening the port would otherwise latch it at the ring size for
	 * good and hide what the ring is doing now, which is the part worth
	 * knowing.
	 *
	 * Exactly one caller may use this -- the statistics packet. Clearing
	 * it in uart_out_get_stats() instead would mean the console log and
	 * the packet each stole half the samples from the other.
	 */
	k_spinlock_key_t key = k_spin_lock(&tx_lock);
	const uint32_t v = s_stats.peak;

	s_stats.peak = 0;
	k_spin_unlock(&tx_lock, key);

	return v;
}
```

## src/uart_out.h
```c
/*
 * uart_out.h - the link to the PC over VCOM1.
 *
 * SPDX-License-Identifier: Apache-2.0
 *
 * Mostly outbound -- it exists to push video at the host -- but the same
 * full-duplex UART carries the operator's control packets the other way, so
 * steering the link needs no second cable.
 */

#ifndef DECTCAM_UART_OUT_H
#define DECTCAM_UART_OUT_H

#include <stdint.h>
#include <stddef.h>

int uart_out_init(void);

/*
 * Called from the UART callback for every chunk the host sends. Runs in
 * interrupt context: keep it short.
 */
typedef void (*uart_out_rx_cb_t)(const uint8_t *data, size_t len);
void uart_out_set_rx_cb(uart_out_rx_cb_t cb);

/*
 * Queue a blob for transmission. Safe to call from an ISR / modem callback:
 * it only touches the ring buffer and signals the pump thread.
 *
 * Returns 0 on success, -ENOSPC if the buffer is full (the blob is dropped
 * whole, never partially, so the PC never sees a torn packet).
 */
int uart_out_send(const uint8_t *data, size_t len);

struct uart_out_stats {
	uint32_t queued;
	uint32_t dropped;
	uint64_t bytes;
	uint32_t peak;	/* high water mark of the ring, in bytes */
};

void uart_out_get_stats(struct uart_out_stats *out);

/* Read and clear the ring high water mark. One caller only: see the note in
 * uart_out.c. */
uint32_t uart_out_take_peak(void);

#endif /* DECTCAM_UART_OUT_H */
```
